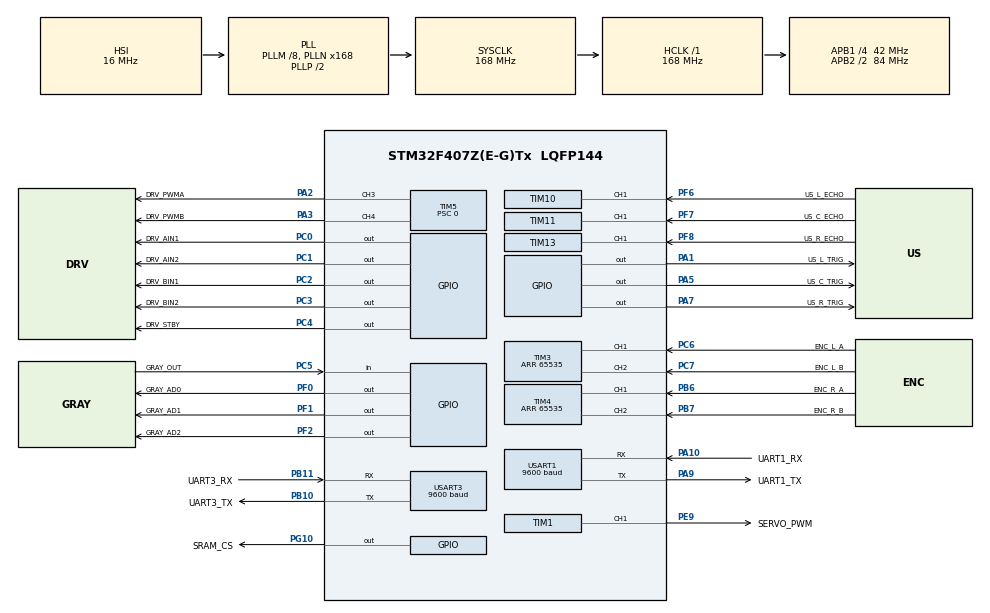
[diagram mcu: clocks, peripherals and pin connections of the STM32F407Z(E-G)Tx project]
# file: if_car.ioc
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Mcu.Family=STM32F4
Mcu.Name=STM32F407Z(E-G)Tx
Mcu.Package=LQFP144
NVIC.PriorityGroup=NVIC_PRIORITYGROUP_4
NVIC.TIM1_TRG_COM_TIM11_IRQn=true\:5\:0\:false\:false\:true\:true\:true\:true
NVIC.TIM1_UP_TIM10_IRQn=true\:5\:0\:false\:false\:true\:true\:true\:true
NVIC.TIM8_UP_TIM13_IRQn=true\:5\:0\:false\:false\:true\:true\:true\:true
NVIC.USART1_IRQn=true\:6\:0\:false\:false\:true\:true\:true\:true
NVIC.USART3_IRQn=true\:6\:0\:false\:false\:true\:true\:true\:true
PA1.GPIO_Label=US_L_TRIG
PA1.Signal=GPIO_Output
PA10.GPIO_Label=UART1_RX
PA10.Mode=Asynchronous
PA10.Signal=USART1_RX
PA13.Mode=Serial_Wire
PA13.Signal=SYS_JTMS-SWDIO
PA14.Mode=Serial_Wire
PA14.Signal=SYS_JTCK-SWCLK
PA2.GPIO_Label=DRV_PWMA
PA2.Signal=S_TIM5_CH3
PA3.GPIO_Label=DRV_PWMB
PA3.Signal=S_TIM5_CH4
PA5.GPIO_Label=US_C_TRIG
PA5.Signal=GPIO_Output
PA7.GPIO_Label=US_R_TRIG
PA7.Signal=GPIO_Output
PA9.GPIO_Label=UART1_TX
PA9.Mode=Asynchronous
PA9.Signal=USART1_TX
PB10.GPIO_Label=UART3_TX
PB10.Mode=Asynchronous
PB10.Signal=USART3_TX
PB11.GPIO_Label=UART3_RX
PB11.Mode=Asynchronous
PB11.Signal=USART3_RX
PB6.GPIO_Label=ENC_R_A
PB6.GPIO_PuPd=GPIO_PULLUP
PB6.Signal=S_TIM4_CH1
PB7.GPIO_Label=ENC_R_B
PB7.GPIO_PuPd=GPIO_PULLUP
PB7.Signal=S_TIM4_CH2
PC0.GPIO_Label=DRV_AIN1
PC0.Signal=GPIO_Output
PC1.GPIO_Label=DRV_AIN2
PC1.Signal=GPIO_Output
PC2.GPIO_Label=DRV_BIN1
PC2.Signal=GPIO_Output
PC3.GPIO_Label=DRV_BIN2
PC3.Signal=GPIO_Output
PC4.GPIO_Label=DRV_STBY
PC4.Signal=GPIO_Output
PC5.GPIO_PuPd=GPIO_NOPULL
PC5.GPIO_Label=GRAY_OUT
PC5.Signal=GPIO_Input
PC6.GPIO_Label=ENC_L_A
PC6.GPIO_PuPd=GPIO_PULLUP
PC6.Signal=S_TIM3_CH1
PC7.GPIO_Label=ENC_L_B
PC7.GPIO_PuPd=GPIO_PULLUP
PC7.Signal=S_TIM3_CH2
PE9.GPIO_Label=SERVO_PWM
PE9.Signal=S_TIM1_CH1
PF0.GPIO_Label=GRAY_AD0
PF0.Signal=GPIO_Output
PF1.GPIO_Label=GRAY_AD1
PF1.Signal=GPIO_Output
PF2.GPIO_Label=GRAY_AD2
PF2.Signal=GPIO_Output
PF6.GPIO_PuPd=GPIO_NOPULL
PF6.GPIO_Label=US_L_ECHO
PF6.Signal=S_TIM10_CH1
PF7.GPIO_PuPd=GPIO_NOPULL
PF7.GPIO_Label=US_C_ECHO
PF7.Signal=S_TIM11_CH1
PF8.GPIO_PuPd=GPIO_NOPULL
PF8.GPIO_Label=US_R_ECHO
PF8.Signal=S_TIM13_CH1
PG10.GPIO_Label=SRAM_CS
PG10.GPIO_PuPd=GPIO_PULLUP
PG10.PinState=GPIO_PIN_SET
PG10.Signal=GPIO_Output
ProjectManager.HeapSize=0x200
ProjectManager.StackSize=0x400
ProjectManager.TargetToolchain=CMake
RCC.48MHZClocksFreq_Value=48000000
RCC.AHBFreq_Value=168000000
RCC.APB1CLKDivider=RCC_HCLK_DIV4
RCC.APB1Freq_Value=42000000
RCC.APB1TimFreq_Value=84000000
RCC.APB2CLKDivider=RCC_HCLK_DIV2
RCC.APB2Freq_Value=84000000
RCC.APB2TimFreq_Value=168000000
RCC.CortexFreq_Value=168000000
RCC.HCLKFreq_Value=168000000
RCC.HSE_VALUE=25000000
RCC.HSI_VALUE=16000000
RCC.LSE_VALUE=32768
RCC.PLLM=8
RCC.PLLN=168
RCC.PLLQ=7
RCC.SYSCLKFreq_VALUE=168000000
RCC.SYSCLKSource=RCC_SYSCLKSOURCE_PLLCLK
RCC.VCOOutputFreq_Value=336000000
SH.S_TIM10_CH1.0=TIM10_CH1,Input_Capture1_from_TI1
SH.S_TIM11_CH1.0=TIM11_CH1,Input_Capture1_from_TI1
SH.S_TIM13_CH1.0=TIM13_CH1,Input_Capture1_from_TI1
SH.S_TIM1_CH1.0=TIM1_CH1,PWM Generation1 CH1
SH.S_TIM3_CH1.0=TIM3_CH1,Encoder_Interface
SH.S_TIM3_CH2.0=TIM3_CH2,Encoder_Interface
SH.S_TIM4_CH1.0=TIM4_CH1,Encoder_Interface
SH.S_TIM4_CH2.0=TIM4_CH2,Encoder_Interface
SH.S_TIM5_CH3.0=TIM5_CH3,PWM Generation3 CH3
SH.S_TIM5_CH4.0=TIM5_CH4,PWM Generation4 CH4
TIM1.Channel-PWM\ Generation1\ CH1=TIM_CHANNEL_1
TIM1.Period=19999
TIM1.Prescaler=167
TIM1.Pulse-PWM\ Generation1\ CH1=1500
TIM10.Channel-Input_Capture1_from_TI1=TIM_CHANNEL_1
TIM10.ICFilter_CH1=4
TIM10.Period=65535
TIM10.Prescaler=167
TIM11.Channel-Input_Capture1_from_TI1=TIM_CHANNEL_1
TIM11.ICFilter_CH1=4
TIM11.Period=65535
TIM11.Prescaler=167
TIM13.Channel-Input_Capture1_from_TI1=TIM_CHANNEL_1
TIM13.ICFilter_CH1=4
TIM13.Period=65535
TIM13.Prescaler=83
TIM3.EncoderMode=TIM_ENCODERMODE_TI12
TIM3.IC1Filter=4
TIM3.IC2Filter=4
TIM3.Period=65535
TIM4.EncoderMode=TIM_ENCODERMODE_TI12
TIM4.IC1Filter=4
TIM4.IC2Filter=4
TIM4.Period=65535
TIM5.Channel-PWM\ Generation3\ CH3=TIM_CHANNEL_3
TIM5.Channel-PWM\ Generation4\ CH4=TIM_CHANNEL_4
TIM5.Period=4199
TIM5.Prescaler=0
TIM5.Pulse-PWM\ Generation3\ CH3=0
TIM5.Pulse-PWM\ Generation4\ CH4=0
USART1.BaudRate=9600
USART1.VirtualMode=VM_ASYNC
USART3.BaudRate=9600
USART3.VirtualMode=VM_ASYNC
VP_TIM10_VS_ClockSourceINT.Mode=Internal
VP_TIM11_VS_ClockSourceINT.Mode=Internal
VP_TIM13_VS_ClockSourceINT.Mode=Internal
VP_TIM1_VS_ClockSourceINT.Mode=Internal
VP_TIM5_VS_ClockSourceINT.Mode=Internal
board=custom

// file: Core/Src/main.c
/* USER CODE BEGIN Header */
/**
  ******************************************************************************
  * @file           : main.c
  * @brief          : Main program body
  ******************************************************************************
  * @attention
  *
  * Copyright (c) 2026 STMicroelectronics.
  * All rights reserved.
  *
  * This software is licensed under terms that can be found in the LICENSE file
  * in the root directory of this software component.
  * If no LICENSE file comes with this software, it is provided AS-IS.
  *
  ******************************************************************************
  */
/* USER CODE END Header */
#include "main.h"

/* USER CODE BEGIN Includes */
#include "car_app.h"
#include "car_config.h"

/* USER CODE END Includes */

TIM_HandleTypeDef htim1;
TIM_HandleTypeDef htim3;
TIM_HandleTypeDef htim5;
TIM_HandleTypeDef htim4;
TIM_HandleTypeDef htim10;
TIM_HandleTypeDef htim11;
TIM_HandleTypeDef htim13;

UART_HandleTypeDef huart1;
UART_HandleTypeDef huart3;

void SystemClock_Config(void);
static void MX_GPIO_Init(void);
static void MX_TIM1_Init(void);
static void MX_TIM3_Init(void);
static void MX_TIM5_Init(void);
static void MX_TIM4_Init(void);
static void MX_TIM10_Init(void);
static void MX_TIM11_Init(void);
static void MX_TIM13_Init(void);
static void MX_USART1_UART_Init(void);
static void MX_USART3_UART_Init(void);

int main(void)
{

  /* MCU Configuration--------------------------------------------------------*/

  /* Reset of all peripherals, Initializes the Flash interface and the Systick. */
  HAL_Init();

  /* Configure the system clock */
  SystemClock_Config();

  /* Initialize all configured peripherals */
  MX_GPIO_Init();
  MX_TIM1_Init();
  MX_TIM3_Init();
  MX_TIM5_Init();
  MX_TIM4_Init();
  MX_TIM10_Init();
  MX_TIM11_Init();
  MX_TIM13_Init();
  MX_USART1_UART_Init();
  MX_USART3_UART_Init();
  /* USER CODE BEGIN 2 */
  if (!CarApp_Init()) Error_Handler();

  /* USER CODE END 2 */

  /* Infinite loop */
  while (1)
  {

    /* USER CODE BEGIN 3 */
    CarApp_Loop();
    HAL_Delay(1);
  }
  /* USER CODE END 3 */
}

void SystemClock_Config(void)
{
  RCC_OscInitTypeDef RCC_OscInitStruct = {0};
  RCC_ClkInitTypeDef RCC_ClkInitStruct = {0};

  /** Configure the main internal regulator output voltage
  */
  __HAL_RCC_PWR_CLK_ENABLE();
  __HAL_PWR_VOLTAGESCALING_CONFIG(PWR_REGULATOR_VOLTAGE_SCALE1);

  /** Initializes the RCC Oscillators according to the specified parameters
  * in the RCC_OscInitTypeDef structure.
  */
  RCC_OscInitStruct.OscillatorType = RCC_OSCILLATORTYPE_HSI;
  RCC_OscInitStruct.HSIState = RCC_HSI_ON;
  RCC_OscInitStruct.HSICalibrationValue = RCC_HSICALIBRATION_DEFAULT;
  RCC_OscInitStruct.PLL.PLLState = RCC_PLL_ON;
  RCC_OscInitStruct.PLL.PLLSource = RCC_PLLSOURCE_HSI;
  RCC_OscInitStruct.PLL.PLLM = 8;
  RCC_OscInitStruct.PLL.PLLN = 168;
  RCC_OscInitStruct.PLL.PLLP = RCC_PLLP_DIV2;
  RCC_OscInitStruct.PLL.PLLQ = 7;
  if (HAL_RCC_OscConfig(&RCC_OscInitStruct) != HAL_OK)
  {
    Error_Handler();
  }

  /** Initializes the CPU, AHB and APB buses clocks
  */
  RCC_ClkInitStruct.ClockType = RCC_CLOCKTYPE_HCLK|RCC_CLOCKTYPE_SYSCLK
                              |RCC_CLOCKTYPE_PCLK1|RCC_CLOCKTYPE_PCLK2;
  RCC_ClkInitStruct.SYSCLKSource = RCC_SYSCLKSOURCE_PLLCLK;
  RCC_ClkInitStruct.AHBCLKDivider = RCC_SYSCLK_DIV1;
  RCC_ClkInitStruct.APB1CLKDivider = RCC_HCLK_DIV4;
  RCC_ClkInitStruct.APB2CLKDivider = RCC_HCLK_DIV2;

  if (HAL_RCC_ClockConfig(&RCC_ClkInitStruct, FLASH_LATENCY_5) != HAL_OK)
  {
    Error_Handler();
  }
}

static void MX_TIM1_Init(void)
{

  TIM_ClockConfigTypeDef sClockSourceConfig = {0};
  TIM_MasterConfigTypeDef sMasterConfig = {0};
  TIM_OC_InitTypeDef sConfigOC = {0};
  TIM_BreakDeadTimeConfigTypeDef sBreakDeadTimeConfig = {0};

  htim1.Instance = TIM1;
  htim1.Init.Prescaler = 167;
  htim1.Init.CounterMode = TIM_COUNTERMODE_UP;
  htim1.Init.Period = CAR_SERVO_PERIOD_US - 1U;
  htim1.Init.ClockDivision = TIM_CLOCKDIVISION_DIV1;
  htim1.Init.RepetitionCounter = 0;
  htim1.Init.AutoReloadPreload = TIM_AUTORELOAD_PRELOAD_DISABLE;
  if (HAL_TIM_Base_Init(&htim1) != HAL_OK)
  {
    Error_Handler();
  }
  sClockSourceConfig.ClockSource = TIM_CLOCKSOURCE_INTERNAL;
  if (HAL_TIM_ConfigClockSource(&htim1, &sClockSourceConfig) != HAL_OK)
  {
    Error_Handler();
  }
  if (HAL_TIM_PWM_Init(&htim1) != HAL_OK)
  {
    Error_Handler();
  }
  sMasterConfig.MasterOutputTrigger = TIM_TRGO_RESET;
  sMasterConfig.MasterSlaveMode = TIM_MASTERSLAVEMODE_DISABLE;
  if (HAL_TIMEx_MasterConfigSynchronization(&htim1, &sMasterConfig) != HAL_OK)
  {
    Error_Handler();
  }
  sConfigOC.OCMode = TIM_OCMODE_PWM1;
  sConfigOC.Pulse = CAR_SERVO_CENTER_US;
  sConfigOC.OCPolarity = TIM_OCPOLARITY_HIGH;
  sConfigOC.OCNPolarity = TIM_OCNPOLARITY_HIGH;
  sConfigOC.OCFastMode = TIM_OCFAST_DISABLE;
  sConfigOC.OCIdleState = TIM_OCIDLESTATE_RESET;
  sConfigOC.OCNIdleState = TIM_OCNIDLESTATE_RESET;
  if (HAL_TIM_PWM_ConfigChannel(&htim1, &sConfigOC, TIM_CHANNEL_1) != HAL_OK)
  {
    Error_Handler();
  }
  sBreakDeadTimeConfig.OffStateRunMode = TIM_OSSR_DISABLE;
  sBreakDeadTimeConfig.OffStateIDLEMode = TIM_OSSI_DISABLE;
  sBreakDeadTimeConfig.LockLevel = TIM_LOCKLEVEL_OFF;
  sBreakDeadTimeConfig.DeadTime = 0;
  sBreakDeadTimeConfig.BreakState = TIM_BREAK_DISABLE;
  sBreakDeadTimeConfig.BreakPolarity = TIM_BREAKPOLARITY_HIGH;
  sBreakDeadTimeConfig.AutomaticOutput = TIM_AUTOMATICOUTPUT_DISABLE;
  if (HAL_TIMEx_ConfigBreakDeadTime(&htim1, &sBreakDeadTimeConfig) != HAL_OK)
  {
    Error_Handler();
  }
  HAL_TIM_MspPostInit(&htim1);

}

static void MX_TIM3_Init(void)
{

  TIM_Encoder_InitTypeDef sConfig = {0};
  TIM_MasterConfigTypeDef sMasterConfig = {0};

  htim3.Instance = TIM3;
  htim3.Init.Prescaler = 0;
  htim3.Init.CounterMode = TIM_COUNTERMODE_UP;
  htim3.Init.Period = 65535;
  htim3.Init.ClockDivision = TIM_CLOCKDIVISION_DIV1;
  htim3.Init.AutoReloadPreload = TIM_AUTORELOAD_PRELOAD_DISABLE;
  sConfig.EncoderMode = TIM_ENCODERMODE_TI12;
  sConfig.IC1Polarity = TIM_ICPOLARITY_RISING;
  sConfig.IC1Selection = TIM_ICSELECTION_DIRECTTI;
  sConfig.IC1Prescaler = TIM_ICPSC_DIV1;
  sConfig.IC1Filter = 4;
  sConfig.IC2Polarity = TIM_ICPOLARITY_RISING;
  sConfig.IC2Selection = TIM_ICSELECTION_DIRECTTI;
  sConfig.IC2Prescaler = TIM_ICPSC_DIV1;
  sConfig.IC2Filter = 4;
  if (HAL_TIM_Encoder_Init(&htim3, &sConfig) != HAL_OK)
  {
    Error_Handler();
  }
  sMasterConfig.MasterOutputTrigger = TIM_TRGO_RESET;
  sMasterConfig.MasterSlaveMode = TIM_MASTERSLAVEMODE_DISABLE;
  if (HAL_TIMEx_MasterConfigSynchronization(&htim3, &sMasterConfig) != HAL_OK)
  {
    Error_Handler();
  }

}

static void MX_TIM5_Init(void)
{

  TIM_ClockConfigTypeDef sClockSourceConfig = {0};
  TIM_MasterConfigTypeDef sMasterConfig = {0};
  TIM_OC_InitTypeDef sConfigOC = {0};

  htim5.Instance = TIM5;
  htim5.Init.Prescaler = 0;
  htim5.Init.CounterMode = TIM_COUNTERMODE_UP;
  htim5.Init.Period = CAR_MOTOR_PERIOD_TICKS - 1U;
  htim5.Init.ClockDivision = TIM_CLOCKDIVISION_DIV1;
  htim5.Init.AutoReloadPreload = TIM_AUTORELOAD_PRELOAD_DISABLE;
  if (HAL_TIM_Base_Init(&htim5) != HAL_OK)
  {
    Error_Handler();
  }
  sClockSourceConfig.ClockSource = TIM_CLOCKSOURCE_INTERNAL;
  if (HAL_TIM_ConfigClockSource(&htim5, &sClockSourceConfig) != HAL_OK)
  {
    Error_Handler();
  }
  if (HAL_TIM_PWM_Init(&htim5) != HAL_OK)
  {
    Error_Handler();
  }
  sMasterConfig.MasterOutputTrigger = TIM_TRGO_RESET;
  sMasterConfig.MasterSlaveMode = TIM_MASTERSLAVEMODE_DISABLE;
  if (HAL_TIMEx_MasterConfigSynchronization(&htim5, &sMasterConfig) != HAL_OK)
  {
    Error_Handler();
  }
  sConfigOC.OCMode = TIM_OCMODE_PWM1;
  sConfigOC.Pulse = 0;
  sConfigOC.OCPolarity = TIM_OCPOLARITY_HIGH;
  sConfigOC.OCFastMode = TIM_OCFAST_DISABLE;
  if (HAL_TIM_PWM_ConfigChannel(&htim5, &sConfigOC, TIM_CHANNEL_3) != HAL_OK)
  {
    Error_Handler();
  }
  if (HAL_TIM_PWM_ConfigChannel(&htim5, &sConfigOC, TIM_CHANNEL_4) != HAL_OK)
  {
    Error_Handler();
  }
  HAL_TIM_MspPostInit(&htim5);

}

static void MX_TIM4_Init(void)
{

  TIM_Encoder_InitTypeDef sConfig = {0};
  TIM_MasterConfigTypeDef sMasterConfig = {0};

  htim4.Instance = TIM4;
  htim4.Init.Prescaler = 0;
  htim4.Init.CounterMode = TIM_COUNTERMODE_UP;
  htim4.Init.Period = 65535;
  htim4.Init.ClockDivision = TIM_CLOCKDIVISION_DIV1;
  htim4.Init.AutoReloadPreload = TIM_AUTORELOAD_PRELOAD_DISABLE;
  sConfig.EncoderMode = TIM_ENCODERMODE_TI12;
  sConfig.IC1Polarity = TIM_ICPOLARITY_RISING;
  sConfig.IC1Selection = TIM_ICSELECTION_DIRECTTI;
  sConfig.IC1Prescaler = TIM_ICPSC_DIV1;
  sConfig.IC1Filter = 4;
  sConfig.IC2Polarity = TIM_ICPOLARITY_RISING;
  sConfig.IC2Selection = TIM_ICSELECTION_DIRECTTI;
  sConfig.IC2Prescaler = TIM_ICPSC_DIV1;
  sConfig.IC2Filter = 4;
  if (HAL_TIM_Encoder_Init(&htim4, &sConfig) != HAL_OK)
  {
    Error_Handler();
  }
  sMasterConfig.MasterOutputTrigger = TIM_TRGO_RESET;
  sMasterConfig.MasterSlaveMode = TIM_MASTERSLAVEMODE_DISABLE;
  if (HAL_TIMEx_MasterConfigSynchronization(&htim4, &sMasterConfig) != HAL_OK)
  {
    Error_Handler();
  }

}

static void MX_TIM10_Init(void)
{

  TIM_IC_InitTypeDef sConfigIC = {0};

  htim10.Instance = TIM10;
  htim10.Init.Prescaler = 167;
  htim10.Init.CounterMode = TIM_COUNTERMODE_UP;
  htim10.Init.Period = 65535;
  htim10.Init.ClockDivision = TIM_CLOCKDIVISION_DIV1;
  htim10.Init.AutoReloadPreload = TIM_AUTORELOAD_PRELOAD_DISABLE;
  if (HAL_TIM_Base_Init(&htim10) != HAL_OK)
  {
    Error_Handler();
  }
  if (HAL_TIM_IC_Init(&htim10) != HAL_OK)
  {
    Error_Handler();
  }
  sConfigIC.ICPolarity = TIM_INPUTCHANNELPOLARITY_RISING;
  sConfigIC.ICSelection = TIM_ICSELECTION_DIRECTTI;
  sConfigIC.ICPrescaler = TIM_ICPSC_DIV1;
  sConfigIC.ICFilter = 4;
  if (HAL_TIM_IC_ConfigChannel(&htim10, &sConfigIC, TIM_CHANNEL_1) != HAL_OK)
  {
    Error_Handler();
  }

}

static void MX_TIM11_Init(void)
{

  TIM_IC_InitTypeDef sConfigIC = {0};

  htim11.Instance = TIM11;
  htim11.Init.Prescaler = 167;
  htim11.Init.CounterMode = TIM_COUNTERMODE_UP;
  htim11.Init.Period = 65535;
  htim11.Init.ClockDivision = TIM_CLOCKDIVISION_DIV1;
  htim11.Init.AutoReloadPreload = TIM_AUTORELOAD_PRELOAD_DISABLE;
  if (HAL_TIM_Base_Init(&htim11) != HAL_OK)
  {
    Error_Handler();
  }
  if (HAL_TIM_IC_Init(&htim11) != HAL_OK)
  {
    Error_Handler();
  }
  sConfigIC.ICPolarity = TIM_INPUTCHANNELPOLARITY_RISING;
  sConfigIC.ICSelection = TIM_ICSELECTION_DIRECTTI;
  sConfigIC.ICPrescaler = TIM_ICPSC_DIV1;
  sConfigIC.ICFilter = 4;
  if (HAL_TIM_IC_ConfigChannel(&htim11, &sConfigIC, TIM_CHANNEL_1) != HAL_OK)
  {
    Error_Handler();
  }

}

static void MX_TIM13_Init(void)
{

  TIM_IC_InitTypeDef sConfigIC = {0};

  htim13.Instance = TIM13;
  htim13.Init.Prescaler = 83;
  htim13.Init.CounterMode = TIM_COUNTERMODE_UP;
  htim13.Init.Period = 65535;
  htim13.Init.ClockDivision = TIM_CLOCKDIVISION_DIV1;
  htim13.Init.AutoReloadPreload = TIM_AUTORELOAD_PRELOAD_DISABLE;
  if (HAL_TIM_Base_Init(&htim13) != HAL_OK)
  {
    Error_Handler();
  }
  if (HAL_TIM_IC_Init(&htim13) != HAL_OK)
  {
    Error_Handler();
  }
  sConfigIC.ICPolarity = TIM_INPUTCHANNELPOLARITY_RISING;
  sConfigIC.ICSelection = TIM_ICSELECTION_DIRECTTI;
  sConfigIC.ICPrescaler = TIM_ICPSC_DIV1;
  sConfigIC.ICFilter = 4;
  if (HAL_TIM_IC_ConfigChannel(&htim13, &sConfigIC, TIM_CHANNEL_1) != HAL_OK)
  {
    Error_Handler();
  }

}

static void MX_USART1_UART_Init(void)
{
  huart1.Instance = USART1;
  huart1.Init.BaudRate = CAR_UART_BAUD;
  huart1.Init.WordLength = UART_WORDLENGTH_8B;
  huart1.Init.StopBits = UART_STOPBITS_1;
  huart1.Init.Parity = UART_PARITY_NONE;
  huart1.Init.Mode = UART_MODE_TX_RX;
  huart1.Init.HwFlowCtl = UART_HWCONTROL_NONE;
  huart1.Init.OverSampling = UART_OVERSAMPLING_16;
  if (HAL_UART_Init(&huart1) != HAL_OK)
  {
    Error_Handler();
  }
}

static void MX_USART3_UART_Init(void)
{

  huart3.Instance = USART3;
  huart3.Init.BaudRate = CAR_UART_BAUD;
  huart3.Init.WordLength = UART_WORDLENGTH_8B;
  huart3.Init.StopBits = UART_STOPBITS_1;
  huart3.Init.Parity = UART_PARITY_NONE;
  huart3.Init.Mode = UART_MODE_TX_RX;
  huart3.Init.HwFlowCtl = UART_HWCONTROL_NONE;
  huart3.Init.OverSampling = UART_OVERSAMPLING_16;
  if (HAL_UART_Init(&huart3) != HAL_OK)
  {
    Error_Handler();
  }

}

static void MX_GPIO_Init(void)
{
  GPIO_InitTypeDef gpio = {0};
  /* USER CODE BEGIN MX_GPIO_Init_1 */
  /* Deassert SRAM CE before PF0..PF2 and PE9 share its address/data bus. */
  __HAL_RCC_GPIOG_CLK_ENABLE();
  HAL_GPIO_WritePin(SRAM_CS_GPIO_Port, SRAM_CS_Pin, GPIO_PIN_SET);
  gpio.Pin = SRAM_CS_Pin;
  gpio.Mode = GPIO_MODE_OUTPUT_PP;
  gpio.Pull = GPIO_PULLUP;
  gpio.Speed = GPIO_SPEED_FREQ_LOW;
  HAL_GPIO_Init(SRAM_CS_GPIO_Port, &gpio);
  /* USER CODE END MX_GPIO_Init_1 */

  __HAL_RCC_GPIOA_CLK_ENABLE();
  __HAL_RCC_GPIOB_CLK_ENABLE();
  __HAL_RCC_GPIOC_CLK_ENABLE();
  __HAL_RCC_GPIOE_CLK_ENABLE();
  __HAL_RCC_GPIOF_CLK_ENABLE();
  HAL_GPIO_WritePin(GPIOC, DRV_AIN1_Pin|DRV_AIN2_Pin|DRV_BIN1_Pin|DRV_BIN2_Pin|DRV_STBY_Pin, GPIO_PIN_RESET);
  HAL_GPIO_WritePin(GPIOA, US_L_TRIG_Pin|US_C_TRIG_Pin|US_R_TRIG_Pin, GPIO_PIN_RESET);
  HAL_GPIO_WritePin(GPIOF, GRAY_AD0_Pin|GRAY_AD1_Pin|GRAY_AD2_Pin, GPIO_PIN_RESET);

  gpio.Mode = GPIO_MODE_OUTPUT_PP;
  gpio.Pull = GPIO_NOPULL;
  gpio.Pin = DRV_AIN1_Pin|DRV_AIN2_Pin|DRV_BIN1_Pin|DRV_BIN2_Pin|DRV_STBY_Pin;
  HAL_GPIO_Init(GPIOC, &gpio);
  gpio.Pin = US_L_TRIG_Pin|US_C_TRIG_Pin|US_R_TRIG_Pin;
  HAL_GPIO_Init(GPIOA, &gpio);
  gpio.Pin = GRAY_AD0_Pin|GRAY_AD1_Pin|GRAY_AD2_Pin;
  HAL_GPIO_Init(GPIOF, &gpio);
  gpio.Pin = GRAY_OUT_Pin;
  gpio.Mode = GPIO_MODE_INPUT;
  HAL_GPIO_Init(GRAY_OUT_GPIO_Port, &gpio);
}

void Error_Handler(void)
{
  /* USER CODE BEGIN Error_Handler_Debug */
  CarApp_EmergencyStop();
  __disable_irq();
  while (1)
  {
  }
  /* USER CODE END Error_Handler_Debug */
}
